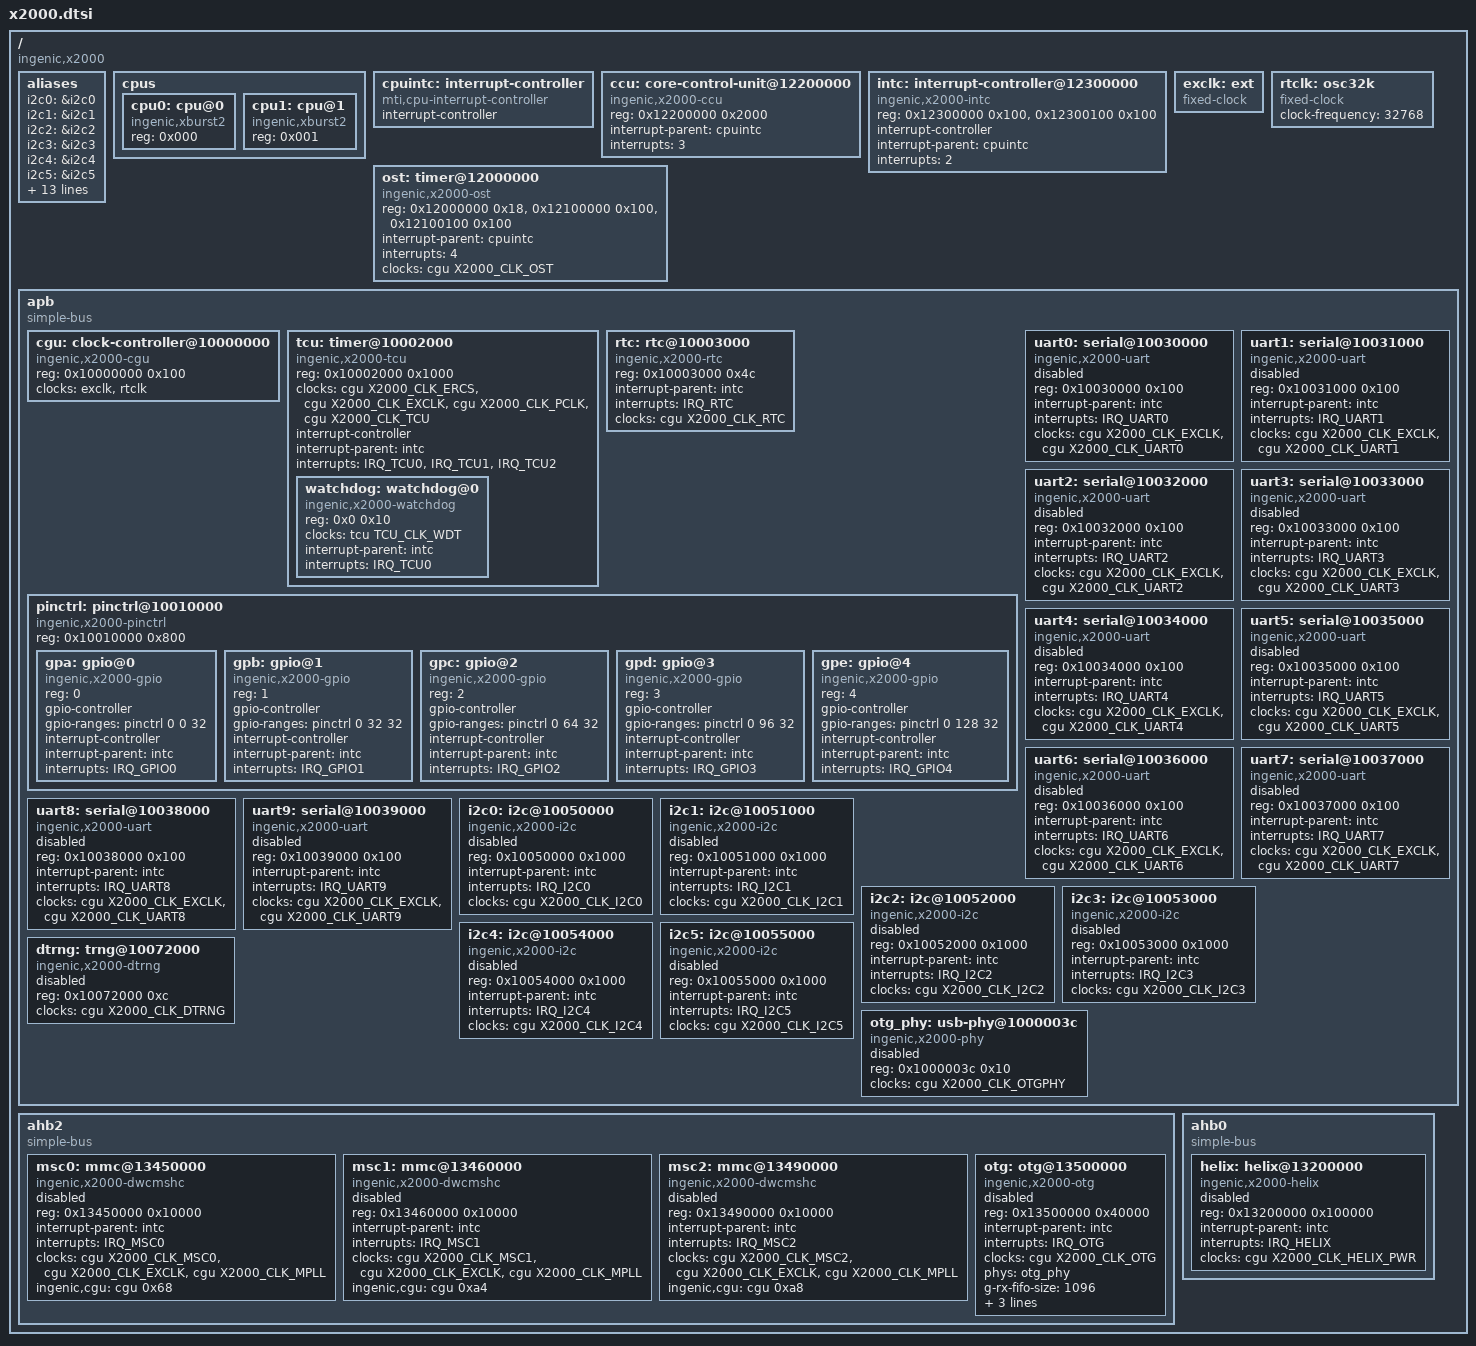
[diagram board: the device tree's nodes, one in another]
// SPDX-License-Identifier: GPL-2.0
/*
 * Ingenic X2000.
 *
 * From the SDK kernel 6.6 (module_drivers/dts/x2000/x2000.dtsi), cut down to
 * the blocks this tree has a driver for. The nodes are in upstream's
 * bindings or, where upstream has none, in the binding of this tree's driver.
 */

#include <dt-bindings/interrupt-controller/x2000-irq.h>
#include <dt-bindings/clock/ingenic,x2000-cgu.h>
#include <dt-bindings/clock/ingenic,tcu.h>

/ {
	#address-cells = <1>;
	#size-cells = <1>;
	compatible = "ingenic,x2000";

	aliases: aliases {
		i2c0 = &i2c0;
		i2c1 = &i2c1;
		i2c2 = &i2c2;
		i2c3 = &i2c3;
		i2c4 = &i2c4;
		i2c5 = &i2c5;
		serial0 = &uart0;
		serial1 = &uart1;
		serial2 = &uart2;
		serial3 = &uart3;
		serial4 = &uart4;
		serial5 = &uart5;
		serial6 = &uart6;
		serial7 = &uart7;
		serial8 = &uart8;
		serial9 = &uart9;
		mmc0 = &msc0;
		mmc1 = &msc1;
		mmc2 = &msc2;
	};

	cpus: cpus {
		#address-cells = <1>;
		#size-cells = <0>;

		cpu0: cpu@0 {
			device_type = "cpu";
			compatible = "ingenic,xburst2";
			reg = <0x000>;
		};

		cpu1: cpu@1 {
			device_type = "cpu";
			compatible = "ingenic,xburst2";
			reg = <0x001>;
		};
	};

	cpuintc: interrupt-controller {
		#address-cells = <0>;
		#interrupt-cells = <1>;
		interrupt-controller;
		compatible = "mti,cpu-interrupt-controller";
	};

	/* the core control unit: the CPUs' resets, sleep states and mailboxes */
	ccu: core-control-unit@12200000 {
		compatible = "ingenic,x2000-ccu";
		reg = <0x12200000 0x2000>;

		/* a mailbox's interrupt is a line of its CPU */
		interrupt-parent = <&cpuintc>;
		interrupts = <3>;
	};

	intc: interrupt-controller@12300000 {
		compatible = "ingenic,x2000-intc";
		/* a block of registers for each CPU */
		reg = <0x12300000 0x100>, <0x12300100 0x100>;
		interrupt-controller;
		#interrupt-cells = <1>;

		interrupt-parent = <&cpuintc>;
		interrupts = <2>;
	};

	/* the SoC's counter, then each CPU's event timer */
	ost: timer@12000000 {
		compatible = "ingenic,x2000-ost";
		reg = <0x12000000 0x18>,
		      <0x12100000 0x100>,
		      <0x12100100 0x100>;
		interrupt-parent = <&cpuintc>;
		interrupts = <4>;
		clocks = <&cgu X2000_CLK_OST>;
		clock-names = "ost";
	};

	/* the crystal; a board says its frequency */
	exclk: ext {
		compatible = "fixed-clock";
		#clock-cells = <0>;
	};

	rtclk: osc32k {
		compatible = "fixed-clock";
		#clock-cells = <0>;
		clock-frequency = <32768>;
	};

	apb {
		compatible = "simple-bus";
		#address-cells = <1>;
		#size-cells = <1>;
		ranges = <>;

		cgu: clock-controller@10000000 {
			compatible = "ingenic,x2000-cgu";
			reg = <0x10000000 0x100>;
			clocks = <&exclk>, <&rtclk>;
			clock-names = "ext", "osc32k";
			#clock-cells = <1>;
		};

		tcu: timer@10002000 {
			compatible = "ingenic,x2000-tcu", "ingenic,x1000-tcu", "simple-mfd";
			reg = <0x10002000 0x1000>;
			#address-cells = <1>;
			#size-cells = <1>;
			ranges = <0x0 0x10002000 0x1000>;

			#clock-cells = <1>;

			clocks = <&cgu X2000_CLK_ERCS>, <&cgu X2000_CLK_EXCLK>,
				 <&cgu X2000_CLK_PCLK>, <&cgu X2000_CLK_TCU>;
			clock-names = "rtc", "ext", "pclk", "tcu";

			interrupt-controller;
			#interrupt-cells = <1>;

			interrupt-parent = <&intc>;
			interrupts = <IRQ_TCU0>, <IRQ_TCU1>, <IRQ_TCU2>;

			watchdog: watchdog@0 {
				compatible = "ingenic,x2000-watchdog";
				reg = <0x0 0x10>;

				clocks = <&tcu TCU_CLK_WDT>;
				clock-names = "wdt";

				/* the TCU's line itself, not one of its channels */
				interrupt-parent = <&intc>;
				interrupts = <IRQ_TCU0>;
			};
		};

		/*
		 * Not a system-power-controller: the power-off is the
		 * board code's (arch/mips/generic/board-ingenic-x2000.c),
		 * which knows the X2000's units for the two times. The clock
		 * is the register gate; its parent is the 32.768 kHz
		 * oscillator the counter runs on.
		 */
		rtc: rtc@10003000 {
			compatible = "ingenic,x2000-rtc", "ingenic,jz4780-rtc";
			reg = <0x10003000 0x4c>;
			interrupt-parent = <&intc>;
			interrupts = <IRQ_RTC>;
			clocks = <&cgu X2000_CLK_RTC>;
			clock-names = "rtc";
		};

		pinctrl: pinctrl@10010000 {
			compatible = "ingenic,x2000-pinctrl";
			reg = <0x10010000 0x800>;
			#address-cells = <1>;
			#size-cells = <0>;

			gpa: gpio@0 {
				compatible = "ingenic,x2000-gpio";
				reg = <0>;

				gpio-controller;
				gpio-ranges = <&pinctrl 0 0 32>;
				#gpio-cells = <2>;

				interrupt-controller;
				#interrupt-cells = <2>;

				interrupt-parent = <&intc>;
				interrupts = <IRQ_GPIO0>;
			};

			gpb: gpio@1 {
				compatible = "ingenic,x2000-gpio";
				reg = <1>;

				gpio-controller;
				gpio-ranges = <&pinctrl 0 32 32>;
				#gpio-cells = <2>;

				interrupt-controller;
				#interrupt-cells = <2>;

				interrupt-parent = <&intc>;
				interrupts = <IRQ_GPIO1>;
			};

			gpc: gpio@2 {
				compatible = "ingenic,x2000-gpio";
				reg = <2>;

				gpio-controller;
				gpio-ranges = <&pinctrl 0 64 32>;
				#gpio-cells = <2>;

				interrupt-controller;
				#interrupt-cells = <2>;

				interrupt-parent = <&intc>;
				interrupts = <IRQ_GPIO2>;
			};

			gpd: gpio@3 {
				compatible = "ingenic,x2000-gpio";
				reg = <3>;

				gpio-controller;
				gpio-ranges = <&pinctrl 0 96 32>;
				#gpio-cells = <2>;

				interrupt-controller;
				#interrupt-cells = <2>;

				interrupt-parent = <&intc>;
				interrupts = <IRQ_GPIO3>;
			};

			gpe: gpio@4 {
				compatible = "ingenic,x2000-gpio";
				reg = <4>;

				gpio-controller;
				gpio-ranges = <&pinctrl 0 128 32>;
				#gpio-cells = <2>;

				interrupt-controller;
				#interrupt-cells = <2>;

				interrupt-parent = <&intc>;
				interrupts = <IRQ_GPIO4>;
			};
		};

		uart0: serial@10030000 {
			compatible = "ingenic,x2000-uart", "ingenic,x1000-uart";
			reg = <0x10030000 0x100>;
			interrupt-parent = <&intc>;
			interrupts = <IRQ_UART0>;
			clocks = <&cgu X2000_CLK_EXCLK>, <&cgu X2000_CLK_UART0>;
			clock-names = "baud", "module";
			status = "disabled";
		};
		uart1: serial@10031000 {
			compatible = "ingenic,x2000-uart", "ingenic,x1000-uart";
			reg = <0x10031000 0x100>;
			interrupt-parent = <&intc>;
			interrupts = <IRQ_UART1>;
			clocks = <&cgu X2000_CLK_EXCLK>, <&cgu X2000_CLK_UART1>;
			clock-names = "baud", "module";
			status = "disabled";
		};
		uart2: serial@10032000 {
			compatible = "ingenic,x2000-uart", "ingenic,x1000-uart";
			reg = <0x10032000 0x100>;
			interrupt-parent = <&intc>;
			interrupts = <IRQ_UART2>;
			clocks = <&cgu X2000_CLK_EXCLK>, <&cgu X2000_CLK_UART2>;
			clock-names = "baud", "module";
			status = "disabled";
		};
		uart3: serial@10033000 {
			compatible = "ingenic,x2000-uart", "ingenic,x1000-uart";
			reg = <0x10033000 0x100>;
			interrupt-parent = <&intc>;
			interrupts = <IRQ_UART3>;
			clocks = <&cgu X2000_CLK_EXCLK>, <&cgu X2000_CLK_UART3>;
			clock-names = "baud", "module";
			status = "disabled";
		};

		uart4: serial@10034000 {
			compatible = "ingenic,x2000-uart", "ingenic,x1000-uart";
			reg = <0x10034000 0x100>;
			interrupt-parent = <&intc>;
			interrupts = <IRQ_UART4>;
			clocks = <&cgu X2000_CLK_EXCLK>, <&cgu X2000_CLK_UART4>;
			clock-names = "baud", "module";
			status = "disabled";
		};
		uart5: serial@10035000 {
			compatible = "ingenic,x2000-uart", "ingenic,x1000-uart";
			reg = <0x10035000 0x100>;
			interrupt-parent = <&intc>;
			interrupts = <IRQ_UART5>;
			clocks = <&cgu X2000_CLK_EXCLK>, <&cgu X2000_CLK_UART5>;
			clock-names = "baud", "module";
			status = "disabled";
		};
		uart6: serial@10036000 {
			compatible = "ingenic,x2000-uart", "ingenic,x1000-uart";
			reg = <0x10036000 0x100>;
			interrupt-parent = <&intc>;
			interrupts = <IRQ_UART6>;
			clocks = <&cgu X2000_CLK_EXCLK>, <&cgu X2000_CLK_UART6>;
			clock-names = "baud", "module";
			status = "disabled";
		};
		uart7: serial@10037000 {
			compatible = "ingenic,x2000-uart", "ingenic,x1000-uart";
			reg = <0x10037000 0x100>;
			interrupt-parent = <&intc>;
			interrupts = <IRQ_UART7>;
			clocks = <&cgu X2000_CLK_EXCLK>, <&cgu X2000_CLK_UART7>;
			clock-names = "baud", "module";
			status = "disabled";
		};

		uart8: serial@10038000 {
			compatible = "ingenic,x2000-uart", "ingenic,x1000-uart";
			reg = <0x10038000 0x100>;
			interrupt-parent = <&intc>;
			interrupts = <IRQ_UART8>;
			clocks = <&cgu X2000_CLK_EXCLK>, <&cgu X2000_CLK_UART8>;
			clock-names = "baud", "module";
			status = "disabled";
		};
		uart9: serial@10039000 {
			compatible = "ingenic,x2000-uart", "ingenic,x1000-uart";
			reg = <0x10039000 0x100>;
			interrupt-parent = <&intc>;
			interrupts = <IRQ_UART9>;
			clocks = <&cgu X2000_CLK_EXCLK>, <&cgu X2000_CLK_UART9>;
			clock-names = "baud", "module";
			status = "disabled";
		};

		i2c0: i2c@10050000 {
			compatible = "ingenic,x2000-i2c", "ingenic,x1000-i2c";
			reg = <0x10050000 0x1000>;
			interrupt-parent = <&intc>;
			interrupts = <IRQ_I2C0>;
			clocks = <&cgu X2000_CLK_I2C0>;
			#address-cells = <1>;
			#size-cells = <0>;
			status = "disabled";
		};

		i2c1: i2c@10051000 {
			compatible = "ingenic,x2000-i2c", "ingenic,x1000-i2c";
			reg = <0x10051000 0x1000>;
			interrupt-parent = <&intc>;
			interrupts = <IRQ_I2C1>;
			clocks = <&cgu X2000_CLK_I2C1>;
			#address-cells = <1>;
			#size-cells = <0>;
			status = "disabled";
		};

		i2c2: i2c@10052000 {
			compatible = "ingenic,x2000-i2c", "ingenic,x1000-i2c";
			reg = <0x10052000 0x1000>;
			interrupt-parent = <&intc>;
			interrupts = <IRQ_I2C2>;
			clocks = <&cgu X2000_CLK_I2C2>;
			#address-cells = <1>;
			#size-cells = <0>;
			status = "disabled";
		};

		i2c3: i2c@10053000 {
			compatible = "ingenic,x2000-i2c", "ingenic,x1000-i2c";
			reg = <0x10053000 0x1000>;
			interrupt-parent = <&intc>;
			interrupts = <IRQ_I2C3>;
			clocks = <&cgu X2000_CLK_I2C3>;
			#address-cells = <1>;
			#size-cells = <0>;
			status = "disabled";
		};

		i2c4: i2c@10054000 {
			compatible = "ingenic,x2000-i2c", "ingenic,x1000-i2c";
			reg = <0x10054000 0x1000>;
			interrupt-parent = <&intc>;
			interrupts = <IRQ_I2C4>;
			clocks = <&cgu X2000_CLK_I2C4>;
			#address-cells = <1>;
			#size-cells = <0>;
			status = "disabled";
		};

		i2c5: i2c@10055000 {
			compatible = "ingenic,x2000-i2c", "ingenic,x1000-i2c";
			reg = <0x10055000 0x1000>;
			interrupt-parent = <&intc>;
			interrupts = <IRQ_I2C5>;
			clocks = <&cgu X2000_CLK_I2C5>;
			#address-cells = <1>;
			#size-cells = <0>;
			status = "disabled";
		};

		dtrng: trng@10072000 {
			compatible = "ingenic,x2000-dtrng";
			reg = <0x10072000 0xc>;
			clocks = <&cgu X2000_CLK_DTRNG>;
			status = "disabled";
		};

		otg_phy: usb-phy@1000003c {
			compatible = "ingenic,x2000-phy";
			reg = <0x1000003c 0x10>;
			clocks = <&cgu X2000_CLK_OTGPHY>;
			#phy-cells = <0>;
			status = "disabled";
		};
	};

	ahb2 {
		compatible = "simple-bus";
		#address-cells = <1>;
		#size-cells = <1>;
		ranges = <>;

		msc0: mmc@13450000 {
			compatible = "ingenic,x2000-dwcmshc";
			reg = <0x13450000 0x10000>;
			interrupt-parent = <&intc>;
			interrupts = <IRQ_MSC0>;
			clocks = <&cgu X2000_CLK_MSC0>, <&cgu X2000_CLK_EXCLK>,
				 <&cgu X2000_CLK_MPLL>;
			clock-names = "core", "ext", "pll";
			ingenic,cgu = <&cgu 0x68>;
			status = "disabled";
		};

		msc1: mmc@13460000 {
			compatible = "ingenic,x2000-dwcmshc";
			reg = <0x13460000 0x10000>;
			interrupt-parent = <&intc>;
			interrupts = <IRQ_MSC1>;
			clocks = <&cgu X2000_CLK_MSC1>, <&cgu X2000_CLK_EXCLK>,
				 <&cgu X2000_CLK_MPLL>;
			clock-names = "core", "ext", "pll";
			ingenic,cgu = <&cgu 0xa4>;
			status = "disabled";
		};

		msc2: mmc@13490000 {
			compatible = "ingenic,x2000-dwcmshc";
			reg = <0x13490000 0x10000>;
			interrupt-parent = <&intc>;
			interrupts = <IRQ_MSC2>;
			clocks = <&cgu X2000_CLK_MSC2>, <&cgu X2000_CLK_EXCLK>,
				 <&cgu X2000_CLK_MPLL>;
			clock-names = "core", "ext", "pll";
			ingenic,cgu = <&cgu 0xa8>;
			status = "disabled";
		};

		otg: otg@13500000 {
			compatible = "ingenic,x2000-otg";
			reg = <0x13500000 0x40000>;
			interrupt-parent = <&intc>;
			interrupts = <IRQ_OTG>;
			clocks = <&cgu X2000_CLK_OTG>;
			clock-names = "otg";
			phys = <&otg_phy>;
			phy-names = "usb2-phy";
			g-rx-fifo-size = <1096>;
			g-np-tx-fifo-size = <512>;
			g-tx-fifo-size = <16 16 16 128 256 256 512 768>;
			otg-rev = <0x200>;
			status = "disabled";
		};
	};

	ahb0 {
		compatible = "simple-bus";
		#address-cells = <1>;
		#size-cells = <1>;
		ranges = <>;

		helix: helix@13200000 {
			compatible = "ingenic,x2000-helix";
			reg = <0x13200000 0x100000>;
			interrupt-parent = <&intc>;
			interrupts = <IRQ_HELIX>;
			/* the codec's power switch, behind its clock gate */
			clocks = <&cgu X2000_CLK_HELIX_PWR>;
			clock-names = "power_helix";
			status = "disabled";
		};
	};
};
